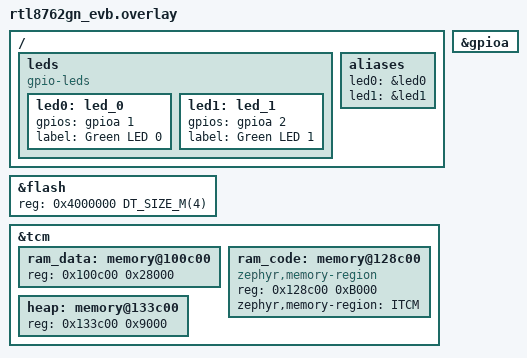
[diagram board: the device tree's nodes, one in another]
/ {
	leds {
		compatible = "gpio-leds";
		led0: led_0 {
			gpios = <&gpioa 1 GPIO_ACTIVE_HIGH>;
			label = "Green LED 0";
		};
		led1: led_1 {
			gpios = <&gpioa 2 GPIO_ACTIVE_HIGH>;
			label = "Green LED 1";
		};
	};

	/* These aliases are provided for compatibility with samples */
	aliases {
		led0 = &led0;
		led1 = &led1;
	};
};

&gpioa {
	status = "okay";
};

&flash {
    reg = <0x4000000 DT_SIZE_M(4)>;
};

&tcm {
    /delete-node/ memory@100c00;
    /delete-node/ memory@119c00;
    /delete-node/ memory@133c00;

    ram_data: memory@100c00 {
        device_type = "ram data region";
        reg = <0x100c00 0x28000>;
    };
    ram_code: memory@128c00 {
        device_type = "ram code region";
        compatible = "zephyr,memory-region", "arm,itcm";
        reg = <0x128c00 0xB000>;
        zephyr,memory-region = "ITCM";
    };
    heap: memory@133c00 {
        device_type = "heap region";
        reg = <0x133c00 0x9000>;
    };
};
